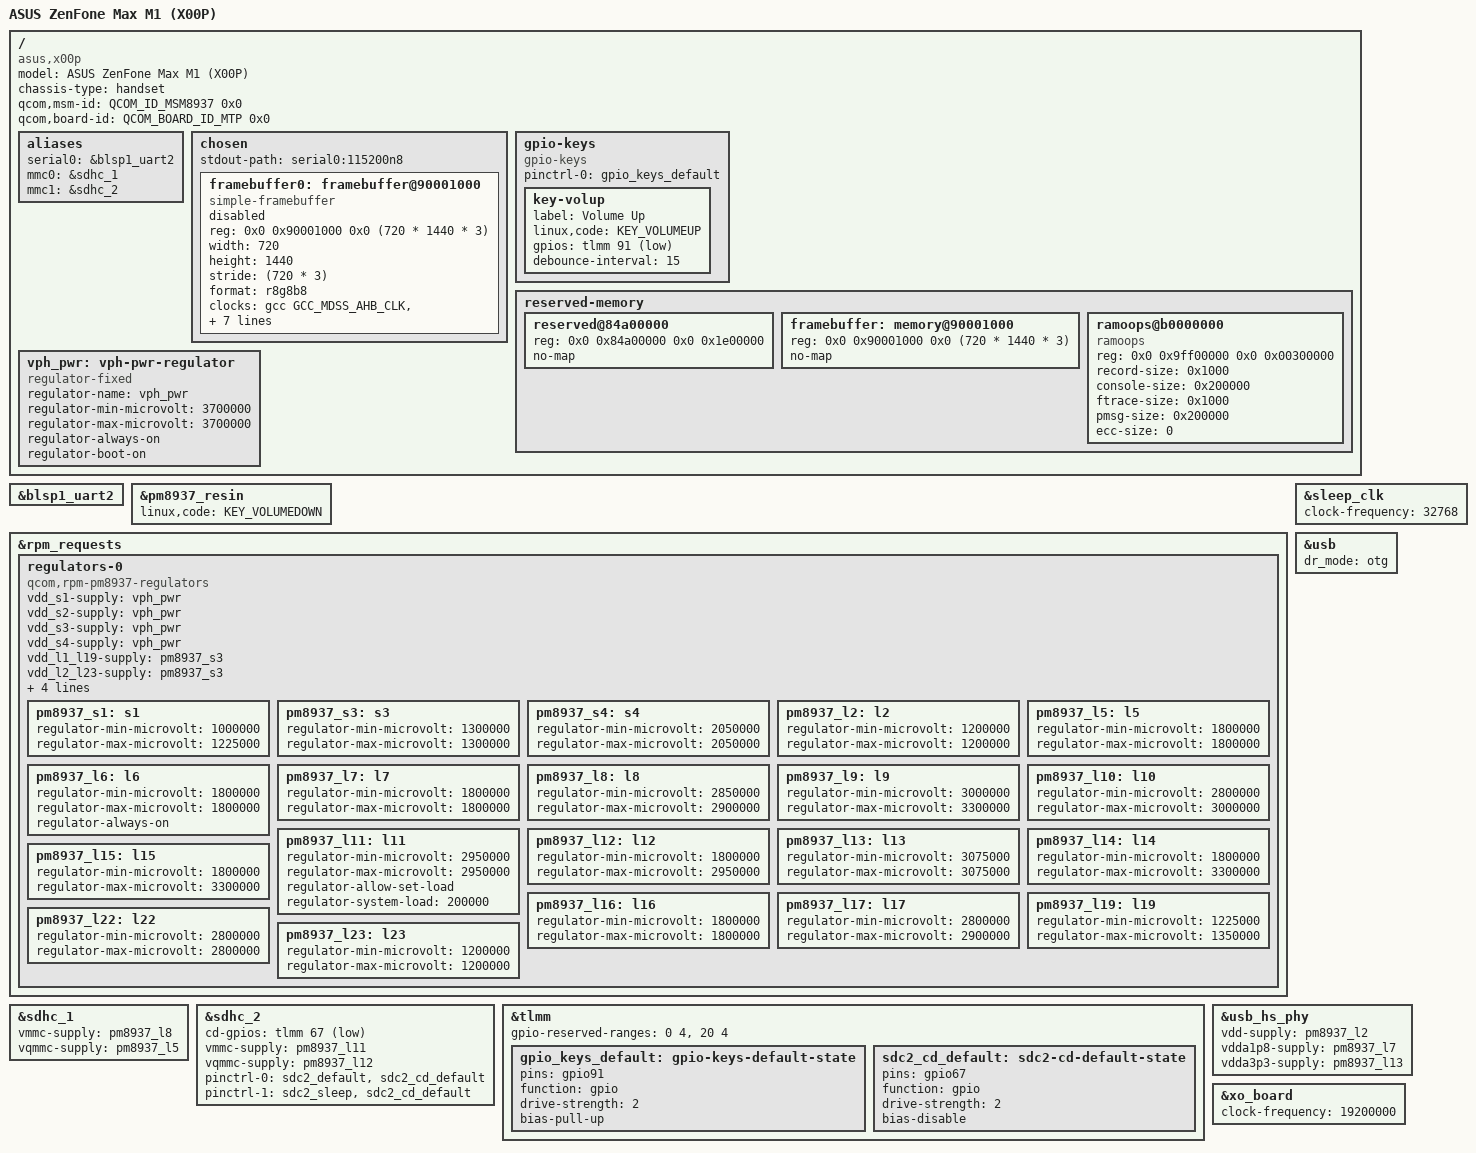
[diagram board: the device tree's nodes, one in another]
// SPDX-License-Identifier: BSD-3-Clause
/*
 * Copyright (c) 2026, Saalim Quadri <danascape@gmail.com>
 *
 * ASUS ZenFone Max M1 (X00P / ZB555KL) - MSM8937 + PMI8940.
 */
/dts-v1/;

#include <dt-bindings/arm/qcom,ids.h>
#include <dt-bindings/gpio/gpio.h>
#include <dt-bindings/input/input.h>

#include "msm8937.dtsi"
#include "pm8937.dtsi"
#include "pmi8950.dtsi"

/delete-node/ &qseecom_mem;

/ {
	model = "ASUS ZenFone Max M1 (X00P)";
	compatible = "asus,x00p", "qcom,msm8937";
	chassis-type = "handset";

	qcom,msm-id = <QCOM_ID_MSM8937 0x0>;
	qcom,board-id = <QCOM_BOARD_ID_MTP 0x0>;

	aliases {
		serial0 = &blsp1_uart2;
		mmc0 = &sdhc_1;
		mmc1 = &sdhc_2;
	};

	chosen {
		#address-cells = <2>;
		#size-cells = <2>;
		ranges;

		stdout-path = "serial0:115200n8";

		framebuffer0: framebuffer@90001000 {
			compatible = "simple-framebuffer";
			reg = <0x0 0x90001000 0x0 (720 * 1440 * 3)>;
			width = <720>;
			height = <1440>;
			stride = <(720 * 3)>;
			format = "r8g8b8";

			clocks = <&gcc GCC_MDSS_AHB_CLK>,
				 <&gcc GCC_MDSS_AXI_CLK>,
				 <&gcc GCC_MDSS_VSYNC_CLK>,
				 <&gcc GCC_MDSS_MDP_CLK>,
				 <&gcc GCC_MDSS_BYTE0_CLK>,
				 <&gcc GCC_MDSS_PCLK0_CLK>,
				 <&gcc GCC_MDSS_ESC0_CLK>;
			power-domains = <&gcc MDSS_GDSC>;
			status = "disabled";
		};
	};

	gpio-keys {
		compatible = "gpio-keys";

		pinctrl-0 = <&gpio_keys_default>;
		pinctrl-names = "default";

		key-volup {
			label = "Volume Up";
			linux,code = <KEY_VOLUMEUP>;
			gpios = <&tlmm 91 GPIO_ACTIVE_LOW>;
			debounce-interval = <15>;
		};
	};

	reserved-memory {
		/* Secure region used by qseecom / TZ apps on X00P */
		reserved@84a00000 {
			reg = <0x0 0x84a00000 0x0 0x1e00000>;
			no-map;
		};

		framebuffer: memory@90001000 {
			reg = <0x0 0x90001000 0x0 (720 * 1440 * 3)>;
			no-map;
		};

		ramoops@b0000000 {
			compatible = "ramoops";
			reg = <0x0 0x9ff00000 0x0 0x00300000>;
			record-size = <0x1000>;
			console-size = <0x200000>;
			ftrace-size = <0x1000>;
			pmsg-size = <0x200000>;
			ecc-size = <0>;
		};
	};

	vph_pwr: vph-pwr-regulator {
		compatible = "regulator-fixed";
		regulator-name = "vph_pwr";
		regulator-min-microvolt = <3700000>;
		regulator-max-microvolt = <3700000>;
		regulator-always-on;
		regulator-boot-on;
	};
};

&blsp1_uart2 {
	status = "okay";
};

&pm8937_resin {
	linux,code = <KEY_VOLUMEDOWN>;
	status = "okay";
};

&rpm_requests {
	regulators-0 {
		compatible = "qcom,rpm-pm8937-regulators";

		vdd_s1-supply = <&vph_pwr>;
		vdd_s2-supply = <&vph_pwr>;
		vdd_s3-supply = <&vph_pwr>;
		vdd_s4-supply = <&vph_pwr>;

		vdd_l1_l19-supply = <&pm8937_s3>;
		vdd_l2_l23-supply = <&pm8937_s3>;
		vdd_l3-supply = <&pm8937_s3>;
		vdd_l4_l5_l6_l7_l16-supply = <&pm8937_s4>;
		vdd_l8_l11_l12_l17_l22-supply = <&vph_pwr>;
		vdd_l9_l10_l13_l14_l15_l18-supply = <&vph_pwr>;

		pm8937_s1: s1 {
			regulator-min-microvolt = <1000000>;
			regulator-max-microvolt = <1225000>;
		};

		pm8937_s3: s3 {
			regulator-min-microvolt = <1300000>;
			regulator-max-microvolt = <1300000>;
		};

		pm8937_s4: s4 {
			regulator-min-microvolt = <2050000>;
			regulator-max-microvolt = <2050000>;
		};

		pm8937_l2: l2 {
			regulator-min-microvolt = <1200000>;
			regulator-max-microvolt = <1200000>;
		};

		pm8937_l5: l5 {
			regulator-min-microvolt = <1800000>;
			regulator-max-microvolt = <1800000>;
		};

		pm8937_l6: l6 {
			regulator-min-microvolt = <1800000>;
			regulator-max-microvolt = <1800000>;
			regulator-always-on;
		};

		pm8937_l7: l7 {
			regulator-min-microvolt = <1800000>;
			regulator-max-microvolt = <1800000>;
		};

		pm8937_l8: l8 {
			regulator-min-microvolt = <2850000>;
			regulator-max-microvolt = <2900000>;
		};

		pm8937_l9: l9 {
			regulator-min-microvolt = <3000000>;
			regulator-max-microvolt = <3300000>;
		};

		pm8937_l10: l10 {
			regulator-min-microvolt = <2800000>;
			regulator-max-microvolt = <3000000>;
		};

		pm8937_l11: l11 {
			regulator-min-microvolt = <2950000>;
			regulator-max-microvolt = <2950000>;
			regulator-allow-set-load;
			regulator-system-load = <200000>;
		};

		pm8937_l12: l12 {
			regulator-min-microvolt = <1800000>;
			regulator-max-microvolt = <2950000>;
		};

		pm8937_l13: l13 {
			regulator-min-microvolt = <3075000>;
			regulator-max-microvolt = <3075000>;
		};

		pm8937_l14: l14 {
			regulator-min-microvolt = <1800000>;
			regulator-max-microvolt = <3300000>;
		};

		pm8937_l15: l15 {
			regulator-min-microvolt = <1800000>;
			regulator-max-microvolt = <3300000>;
		};

		pm8937_l16: l16 {
			regulator-min-microvolt = <1800000>;
			regulator-max-microvolt = <1800000>;
		};

		pm8937_l17: l17 {
			regulator-min-microvolt = <2800000>;
			regulator-max-microvolt = <2900000>;
		};

		pm8937_l19: l19 {
			regulator-min-microvolt = <1225000>;
			regulator-max-microvolt = <1350000>;
		};

		pm8937_l22: l22 {
			regulator-min-microvolt = <2800000>;
			regulator-max-microvolt = <2800000>;
		};

		pm8937_l23: l23 {
			regulator-min-microvolt = <1200000>;
			regulator-max-microvolt = <1200000>;
		};
	};
};

&sdhc_1 {
	vmmc-supply = <&pm8937_l8>;
	vqmmc-supply = <&pm8937_l5>;
	status = "okay";
};

&sdhc_2 {
	cd-gpios = <&tlmm 67 GPIO_ACTIVE_LOW>;
	vmmc-supply = <&pm8937_l11>;
	vqmmc-supply = <&pm8937_l12>;
	pinctrl-0 = <&sdc2_default &sdc2_cd_default>;
	pinctrl-1 = <&sdc2_sleep &sdc2_cd_default>;
	pinctrl-names = "default", "sleep";
	status = "okay";
};

&sleep_clk {
	clock-frequency = <32768>;
};

&tlmm {
	gpio-reserved-ranges = <0 4>, <20 4>;

	gpio_keys_default: gpio-keys-default-state {
		pins = "gpio91";
		function = "gpio";
		drive-strength = <2>;
		bias-pull-up;
	};

	sdc2_cd_default: sdc2-cd-default-state {
		pins = "gpio67";
		function = "gpio";
		drive-strength = <2>;
		bias-disable;
	};
};

&usb {
	dr_mode = "otg";
	status = "okay";
};

&usb_hs_phy {
	vdd-supply = <&pm8937_l2>;
	vdda1p8-supply = <&pm8937_l7>;
	vdda3p3-supply = <&pm8937_l13>;
	status = "okay";
};

&xo_board {
	clock-frequency = <19200000>;
};
